# npck3m7k register map
Registers are 8-bit, read-write, no defined reset value unless marked. A register's access mark holds for its fields unless they carry their own. Offsets are from the block's base; [hi:lo] are bit positions; {n}, {i} and the like mark numbered series.

## SCFG — SYSTEM CONFIGURATION
Base 0x400C3000
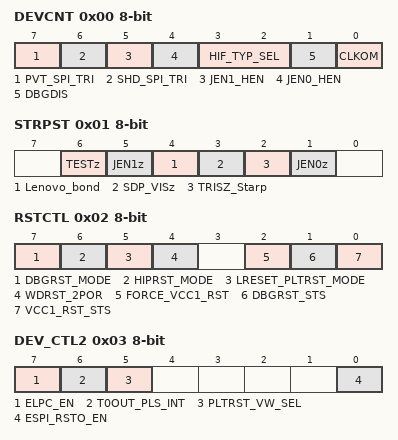
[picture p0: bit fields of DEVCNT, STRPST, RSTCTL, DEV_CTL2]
0x00 DEVCNT
  [7] PVT_SPI_TRI, [6] SHD_SPI_TRI, [5] JEN1_HEN, [4] JEN0_HEN, [3:2] HIF_TYP_SEL, [1] DBGDIS, [0] CLKOM
0x01 STRPST
  [6] TESTz, [5] JEN1z, [4] Lenovo_bond, [3] SDP_VISz, [2] TRISZ_Starp, [1] JEN0z
0x02 RSTCTL
  [7] DBGRST_MODE, [6] HIPRST_MODE, [5] LRESET_PLTRST_MODE, [4] WDRST_2POR, [2] FORCE_VCC1_RST, [1] DBGRST_STS, [0] VCC1_RST_STS
0x03 DEV_CTL2
  [7] ELPC_EN, [6] T0OUT_PLS_INT, [5] PLTRST_VW_SEL, [0] ESPI_RSTO_EN
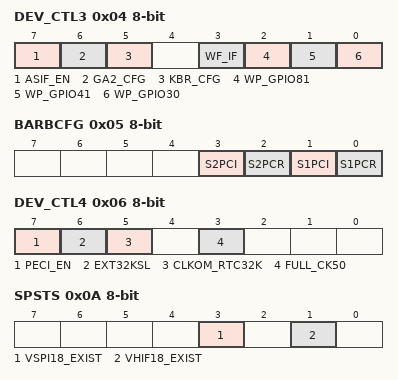
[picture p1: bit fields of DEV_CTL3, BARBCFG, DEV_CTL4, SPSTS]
0x04 DEV_CTL3
  [7] ASIF_EN, [6] GA2_CFG, [5] KBR_CFG, [3] WF_IF, [2] WP_GPIO81, [1] WP_GPIO41, [0] WP_GPIO30
0x05 BARBCFG
  [3] S2PCI, [2] S2PCR, [1] S1PCI, [0] S1PCR
0x06 DEV_CTL4
  [7] PECI_EN, [6] EXT32KSL, [5] CLKOM_RTC32K, [3] FULL_CK50
0x0A SPSTS
  [3] VSPI18_EXIST, [1] VHIF18_EXIST
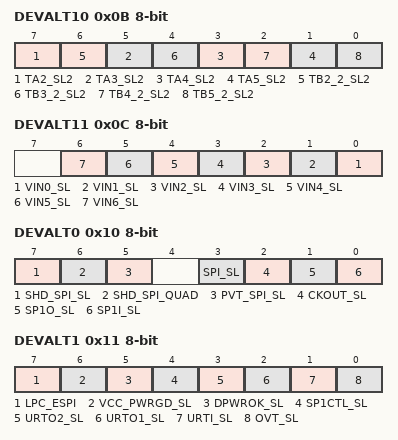
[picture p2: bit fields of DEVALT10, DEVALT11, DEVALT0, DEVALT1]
0x0B DEVALT10
  [11-2n] TA{n}_SL2 (n=2..5), [10-2n] TB{n}_2_SL2 (n=2..5)
0x0C DEVALT11
  [n] VIN{n}_SL (n=0..6)
0x10 DEVALT0
  [7] SHD_SPI_SL, [6] SHD_SPI_QUAD, [5] PVT_SPI_SL, [3] SPI_SL, [2] CKOUT_SL, [1] SP1O_SL, [0] SP1I_SL
0x11 DEVALT1
  [7] LPC_ESPI, [6] VCC_PWRGD_SL, [5] DPWROK_SL, [4] SP1CTL_SL, [3] URTO2_SL, [2] URTO1_SL, [1] URTI_SL, [0] OVT_SL
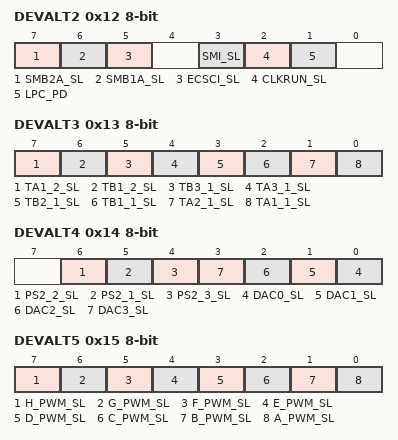
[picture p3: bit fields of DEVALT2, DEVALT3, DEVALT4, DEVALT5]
0x12 DEVALT2
  [7] SMB2A_SL, [6] SMB1A_SL, [5] ECSCI_SL, [3] SMI_SL, [2] CLKRUN_SL, [1] LPC_PD
0x13 DEVALT3
  [7] TA1_2_SL, [6] TB1_2_SL, [5] TB3_1_SL, [4] TA3_1_SL, [3] TB2_1_SL, [2] TB1_1_SL, [1] TA2_1_SL, [0] TA1_1_SL
0x14 DEVALT4
  [6] PS2_2_SL, [5] PS2_1_SL, [4] PS2_3_SL, [n] DAC{n}_SL (n=0..3)
0x15 DEVALT5
  [7] H_PWM_SL, [6] G_PWM_SL, [5] F_PWM_SL, [4] E_PWM_SL, [3] D_PWM_SL, [2] C_PWM_SL, [1] B_PWM_SL, [0] A_PWM_SL
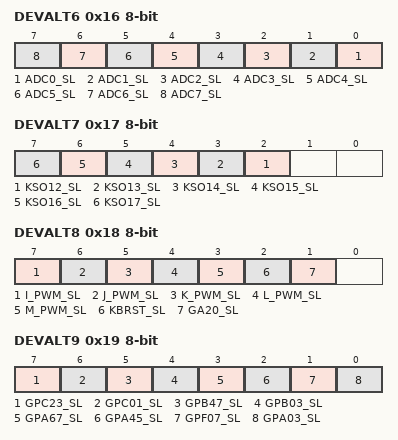
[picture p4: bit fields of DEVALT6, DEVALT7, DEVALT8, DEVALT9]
0x16 DEVALT6
  [n] ADC{n}_SL (n=0..7)
0x17 DEVALT7
  [n-10] KSO{n}_SL (n=12..17)
0x18 DEVALT8
  [7] I_PWM_SL, [6] J_PWM_SL, [5] K_PWM_SL, [4] L_PWM_SL, [3] M_PWM_SL, [2] KBRST_SL, [1] GA20_SL
0x19 DEVALT9
  [7] GPC23_SL, [6] GPC01_SL, [5] GPB47_SL, [4] GPB03_SL, [3] GPA67_SL, [2] GPA45_SL, [1] GPF07_SL, [0] GPA03_SL
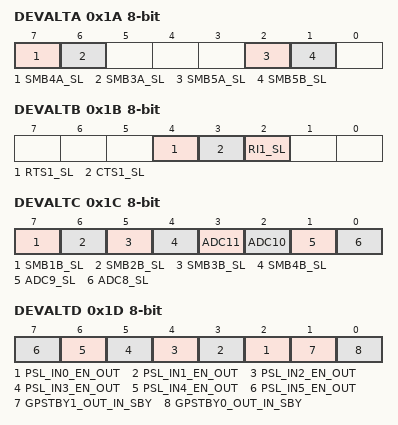
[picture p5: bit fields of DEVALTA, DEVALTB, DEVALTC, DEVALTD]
0x1A DEVALTA
  [7] SMB4A_SL, [6] SMB3A_SL, [2] SMB5A_SL, [1] SMB5B_SL
0x1B DEVALTB
  [4] RTS1_SL, [3] CTS1_SL, [2] RI1_SL
0x1C DEVALTC
  [8-n] SMB{n}B_SL (n=1..4), [3] ADC11, [2] ADC10, [1] ADC9_SL, [0] ADC8_SL
0x1D DEVALTD
  [n+2] PSL_IN{n}_EN_OUT (n=0..5), [1] GPSTBY1_OUT_IN_SBY, [0] GPSTBY0_OUT_IN_SBY
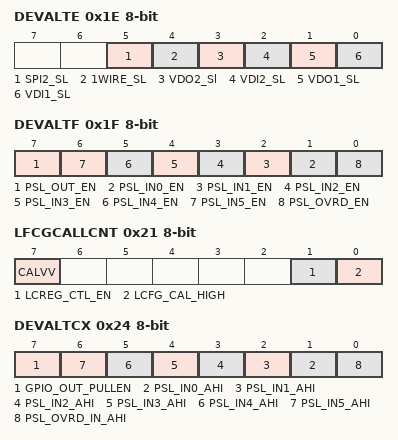
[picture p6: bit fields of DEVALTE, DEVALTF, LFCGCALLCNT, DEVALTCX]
0x1E DEVALTE
  [5] SPI2_SL, [4] 1WIRE_SL, [3] VDO2_Sl, [2] VDI2_SL, [1] VDO1_SL, [0] VDI1_SL
0x1F DEVALTF
  [7] PSL_OUT_EN, [n+1] PSL_IN{n}_EN (n=0..5), [0] PSL_OVRD_EN
0x20 LFCGCALL
  [7:0] LCFG_CAL_LOW
0x21 LFCGCALLCNT
  [7] CALVV, [1] LCREG_CTL_EN, [0] LCFG_CAL_HIGH
0x24 DEVALTCX
  [7] GPIO_OUT_PULLEN, [n+1] PSL_IN{n}_AHI (n=0..5), [0] PSL_OVRD_IN_AHI
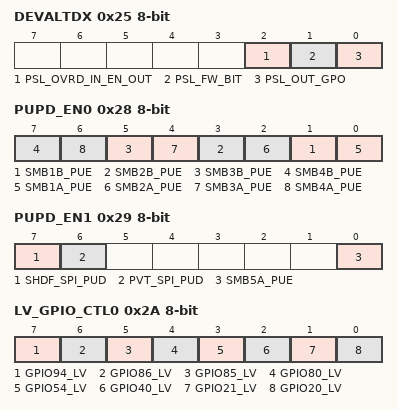
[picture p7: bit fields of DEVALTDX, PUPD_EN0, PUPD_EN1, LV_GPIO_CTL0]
0x25 DEVALTDX
  [2] PSL_OVRD_IN_EN_OUT, [1] PSL_FW_BIT, [0] PSL_OUT_GPO
0x28 PUPD_EN0
  [2n-1] SMB{n}B_PUE (n=1..4), [2n-2] SMB{n}A_PUE (n=1..4)
0x29 PUPD_EN1
  [7] SHDF_SPI_PUD, [6] PVT_SPI_PUD, [0] SMB5A_PUE
0x2A LV_GPIO_CTL0
  [7] GPIO94_LV, [6] GPIO86_LV, [5] GPIO85_LV, [4] GPIO80_LV, [3] GPIO54_LV, [2] GPIO40_LV, [1] GPIO21_LV, [0] GPIO20_LV
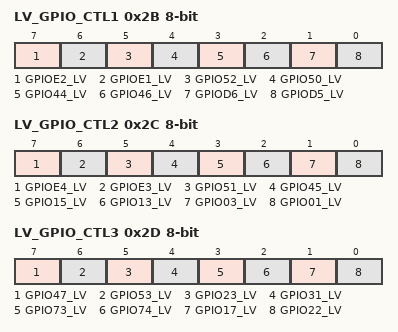
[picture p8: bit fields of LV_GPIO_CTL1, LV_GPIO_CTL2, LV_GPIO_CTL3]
0x2B LV_GPIO_CTL1
  [7] GPIOE2_LV, [6] GPIOE1_LV, [5] GPIO52_LV, [4] GPIO50_LV, [3] GPIO44_LV, [2] GPIO46_LV, [1] GPIOD6_LV, [0] GPIOD5_LV
0x2C LV_GPIO_CTL2
  [7] GPIOE4_LV, [6] GPIOE3_LV, [5] GPIO51_LV, [4] GPIO45_LV, [3] GPIO15_LV, [2] GPIO13_LV, [1] GPIO03_LV, [0] GPIO01_LV
0x2D LV_GPIO_CTL3
  [7] GPIO47_LV, [6] GPIO53_LV, [5] GPIO23_LV, [4] GPIO31_LV, [3] GPIO73_LV, [2] GPIO74_LV, [1] GPIO17_LV, [0] GPIO22_LV
0x2F SCFG_VER

## DBG — Debug Support
Base 0x400C3000
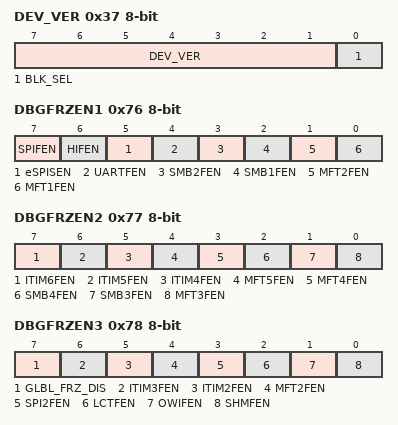
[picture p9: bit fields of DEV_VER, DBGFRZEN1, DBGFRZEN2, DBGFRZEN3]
0x37 DEV_VER
  [7:1] DEV_VER, [0] BLK_SEL
0x74 DBG_CTL
  [2] CLKLP_DBGCOPN
0x76 DBGFRZEN1
  [7] SPIFEN, [6] HIFEN, [5] eSPISEN, [4] UARTFEN, [3] SMB2FEN, [2] SMB1FEN, [1] MFT2FEN, [0] MFT1FEN
0x77 DBGFRZEN2
  [7] ITIM6FEN, [6] ITIM5FEN, [5] ITIM4FEN, [4] MFT5FEN, [3] MFT4FEN, [2] SMB4FEN, [1] SMB3FEN, [0] MFT3FEN
0x78 DBGFRZEN3
  [7] GLBL_FRZ_DIS, [6] ITIM3FEN, [5] ITIM2FEN, [4] MFT2FEN, [3] SPI2FEN, [2] LCTFEN, [1] OWIFEN, [0] SHMFEN
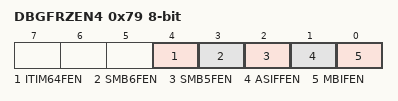
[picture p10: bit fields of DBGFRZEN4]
0x79 DBGFRZEN4
  [4] ITIM64FEN, [3] SMB6FEN, [2] SMB5FEN, [1] ASIFFEN, [0] MBIFEN
